# BE-U1000 register map
Vendor: BAIKAL ELECTRONICS, JSC; File version: 1.0
CPU: RISC-V r0p0, little endian, no MPU, no FPU, 3 interrupt priority bits
Registers are 32-bit, read-write, reset 0x0 unless marked. A register's access mark holds for its fields unless they carry their own. Offsets are from the block's base; [hi:lo] are bit positions.

## I2C0 — Inter Integrated Circuit Interface
Base 0x11004000
Same registers: I2C1 0x11005000, I2C2 0x13004000, I2C3 0x13005000
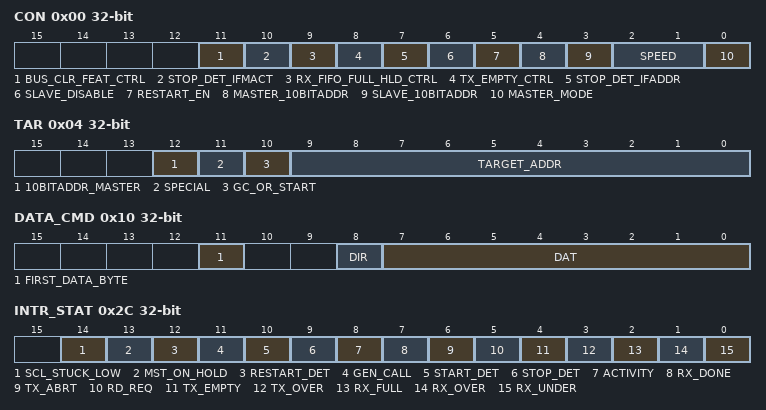
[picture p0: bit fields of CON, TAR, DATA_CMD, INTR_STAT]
0x00 CON — Control Register
  [11] BUS_CLR_FEAT_CTRL — Bus clear feature control
    0=DISABLE; 1=ENABLE
  [10] STOP_DET_IFMACT — STOP_DET interrupt mode if master active
    0=DISABLE; 1=ENABLE
  [9] RX_FIFO_FULL_HLD_CTRL — Hold bus when RX_FIFO is full
    0=DISABLE; 1=ENABLE
  [8] TX_EMPTY_CTRL — TX_EMPTY interrupt control
    0=DISABLE; 1=ENABLE
  [7] STOP_DET_IFADDR — STOP_DET interrupt mode if addressed
    0=DISABLE; 1=ENABLE
  [6] SLAVE_DISABLE — Slave mode disable
    0=DISABLE; 1=ENABLE
  [5] RESTART_EN — Master restart enable
    0=DISABLE; 1=ENABLE
  [4] MASTER_10BITADDR — Master addressing mode
    0=DISABLE; 1=ENABLE
  [3] SLAVE_10BITADDR — Slave addressing mode
    0=DISABLE; 1=ENABLE
  [2:1] SPEED — Bus speed
    1=STANDARD (Standard speed mode of operation); 2=FAST (Fast or Fast Plus speed mode of operation); 3=HIGH (High speed mode of operation)
  [0] MASTER_MODE — Master mode enable
    0=DISABLE; 1=ENABLE
0x04 TAR — Target Address Register
  [12] 10BITADDR_MASTER — Master addressing mode
    0=DISABLE; 1=ENABLE
  [11] SPECIAL — Select Device_ID or GC_OR_START to perform
    0=DISABLE; 1=ENABLE
  [10] GC_OR_START — Select GENERAL_CALL or START byte transmission
    0=DISABLE; 1=ENABLE
  [9:0] TARGET_ADDR — Target address
0x08 SAR — Slave Address Register
  [9:0] SLAVE_ADDR — Slave address
0x0C HS_MADDR — High Speed Master Mode Code Address Register
  [2:0] MASTER_CODE — HS mode master code
0x10 DATA_CMD — Rx/Tx Data Buffer and Command Register
  [11] FIRST_DATA_BYTE — Indicates the first data byte received after the address phase for receive transfer
    0=DISABLE; 1=ENABLE
  [8] DIR — Read or write select
    0=WRITE (Write command); 1=READ (Read command)
  [7:0] DAT — The data to be transmitted or received
0x14 SS_SCL_HCNT — Standard Speed SCL High Count Register
  [15:0] SS_SCL_HCNT — SCL clock high period count for standard speed
0x18 SS_SCL_LCNT — Standard Speed SCL Low Count Register
  [15:0] SS_SCL_LCNT — SCL clock low period count for standard speed
0x1C FS_SCL_HCNT — Fast Mode SCL High Count Register
  [15:0] FS_SCL_HCNT — SCL clock high period count for fast speed
0x20 FS_SCL_LCNT — Fast Mode SCL Low Count Register
  [15:0] FS_SCL_LCNT — SCL clock low period count for fast speed
0x24 HS_SCL_HCNT — High Speed SCL High Count Register
  [15:0] HS_SCL_HCNT — SCL clock high period count for high speed
0x28 HS_SCL_LCNT — High Speed SCL Low Count Register
  [15:0] HS_SCL_LCNT — SCL clock low period count for high speed
0x2C INTR_STAT — Interrupt Status Register
  [all] fields
    0=DISABLE; 1=ENABLE
  [14] SCL_STUCK_LOW — SCL_STUCK_AT_LOW interrupt status
  [13] MST_ON_HOLD — MASTER_ON_HOLD interrupt status
  [12] RESTART_DET — RESTART_DET interrupt status
  [11] GEN_CALL — GEN_CALL interrupt status
  [10] START_DET — START_DET interrupt status
  [9] STOP_DET — STOP_DET interrupt status
  [8] ACTIVITY — ACTIVITY interrupt status
  [7] RX_DONE — RX_DONE interrupt status
  [6] TX_ABRT — TX_ABRT interrupt status
  [5] RD_REQ — RD_REQ interrupt status
  [4] TX_EMPTY — TX_EMPTY interrupt status
  [3] TX_OVER — TX_OVER interrupt status
  [2] RX_FULL — RX_FULL interrupt status
  [1] RX_OVER — RX_OVER interrupt status
  [0] RX_UNDER — RX_UNDER interrupt status
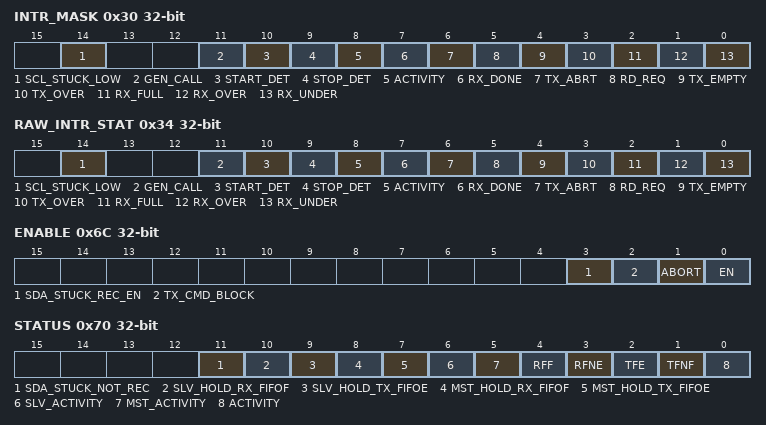
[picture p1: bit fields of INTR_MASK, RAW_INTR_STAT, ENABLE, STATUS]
0x30 INTR_MASK — Interrupt Mask Register
  [all] fields
    0=DISABLE; 1=ENABLE
  [14] SCL_STUCK_LOW — SCL_STUCK_AT_LOW interrupt mask
  [11] GEN_CALL — GEN_CALL interrupt mask
  [10] START_DET — START_DET interrupt mask
  [9] STOP_DET — STOP_DET interrupt mask
  [8] ACTIVITY — ACTIVITY interrupt mask
  [7] RX_DONE — RX_DONE interrupt mask
  [6] TX_ABRT — TX_ABRT interrupt mask
  [5] RD_REQ — RD_REQ interrupt mask
  [4] TX_EMPTY — TX_EMPTY interrupt mask
  [3] TX_OVER — TX_OVER interrupt mask
  [2] RX_FULL — RX_FULL interrupt mask
  [1] RX_OVER — RX_OVER interrupt mask
  [0] RX_UNDER — RX_UNDER interrupt mask
0x34 RAW_INTR_STAT — Raw Interrupt Status Register
  [all] fields
    0=DISABLE; 1=ENABLE
  [14] SCL_STUCK_LOW — SCL_STUCK_AT_LOW interrupt status
  [11] GEN_CALL — GEN_CALL interrupt status
  [10] START_DET — START_DET interrupt status
  [9] STOP_DET — STOP_DET interrupt status
  [8] ACTIVITY — ACTIVITY interrupt status
  [7] RX_DONE — RX_DONE interrupt status
  [6] TX_ABRT — TX_ABRT interrupt status
  [5] RD_REQ — RD_REQ interrupt status
  [4] TX_EMPTY — TX_EMPTY interrupt status
  [3] TX_OVER — TX_OVER interrupt status
  [2] RX_FULL — RX_FULL interrupt status
  [1] RX_OVER — RX_OVER interrupt status
  [0] RX_UNDER — RX_UNDER interrupt status
0x38 RX_TL — Rx FIFO Threshold Register
  [7:0] RX_TL — Rx FIFO threshold level
0x3C TX_TL — Tx FIFO Threshold Register
  [7:0] TX_TL — Tx FIFO threshold level
0x40 CLR_INTR — Clear Combined and Individual Interrupt Register
  [0] CLR_INTR — Clear the combined interrupt, all individual interrupts and TX_ABRT_SOURCE register
    0=DISABLE; 1=ENABLE
0x44 CLR_RX_UNDER — Clear RX_UNDER Interrupt Register
  [0] CLR_RX_UNDER — Clear RX_UNDER interrupt
    0=DISABLE; 1=ENABLE
0x48 CLR_RX_OVER — Clear RX_OVER Interrupt Register
  [0] CLR_RX_OVER — Clear RX_OVER interrupt
    0=DISABLE; 1=ENABLE
0x4C CLR_TX_OVER — Clear TX_OVER Interrupt Register
  [0] CLR_TX_OVER — Clear TX_OVER interrupt
    0=DISABLE; 1=ENABLE
0x50 CLR_RD_REQ — Clear RD_REQ Interrupt Register
  [0] CLR_RD_REQ — Clear RD_REQ interrupt
    0=DISABLE; 1=ENABLE
0x54 CLR_TX_ABRT — Clear TX_ABRT Interrupt Register
  [0] CLR_TX_ABRT — Clear TX_ABRT interrupt and TX_ABRT_SOURCE register
    0=DISABLE; 1=ENABLE
0x58 CLR_RX_DONE — Clear RX_DONE Interrupt Register
  [0] CLR_RX_DONE — Clear RX_DONE interrupt
    0=DISABLE; 1=ENABLE
0x5C CLR_ACTIVITY — Clear ACTIVITY Interrupt Register
  [0] CLR_ACTIVITY — Clear ACTIVITY interrupt
    0=DISABLE; 1=ENABLE
0x60 CLR_STOP_DET — Clear STOP_DET Interrupt Register
  [0] CLR_STOP_DET — Clear STOP_DET interrupt
    0=DISABLE; 1=ENABLE
0x64 CLR_START_DET — Clear START_DET Interrupt Register
  [0] CLR_START_DET — Clear START_DET interrupt
    0=DISABLE; 1=ENABLE
0x68 CLR_GEN_CALL — Clear GEN_CALL Interrupt Register
  [0] CLR_GEN_CALL — Clear GEN_CALL interrupt
    0=DISABLE; 1=ENABLE
0x6C ENABLE
  [all] fields
    0=DISABLE; 1=ENABLE
  [3] SDA_STUCK_REC_EN — Initiate SDA recovery mechanism
  [2] TX_CMD_BLOCK — Block the transmission of data
  [1] ABORT — Initiate the transfer abort
  [0] EN — Enable I2C
0x70 STATUS
  [all] fields
    0=DISABLE; 1=ENABLE
  [11] SDA_STUCK_NOT_REC — SDA stuck at low is not recovered after the recovery mechanism
  [10] SLV_HOLD_RX_FIFOF — BUS Hold due to Rx FIFO is full and an additional byte received
  [9] SLV_HOLD_TX_FIFOE — BUS Hold for the read request when Tx FIFO is empty
  [8] MST_HOLD_RX_FIFOF — BUS Hold due to Rx FIFO is full and an additional byte received
  [7] MST_HOLD_TX_FIFOE — Stall the write transfer when Tx FIFO is empty, no stop bit after the last byte
  [6] SLV_ACTIVITY — Slave FSM activity status
  [5] MST_ACTIVITY — Master FSM activity status
  [4] RFF — Rx FIFO completely full
  [3] RFNE — Rx FIFO not empty
  [2] TFE — Tx FIFO completely empty
  [1] TFNF — Tx FIFO not full
  [0] ACTIVITY — I2C activity status
0x74 TXFLR — Tx FIFO Level Register
  [3:0] TXFLR — Tx FIFO level
0x78 RXFLR — Rx FIFO Level Register
  [3:0] RXFLR — Rx FIFO level
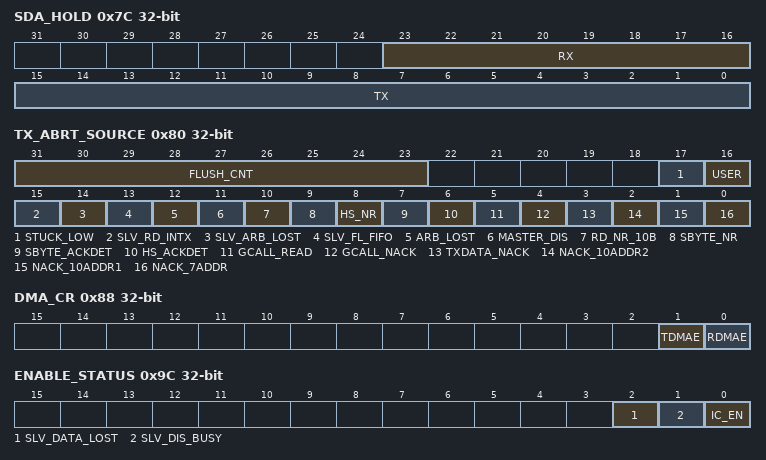
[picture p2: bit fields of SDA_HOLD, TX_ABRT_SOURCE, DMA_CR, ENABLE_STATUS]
0x7C SDA_HOLD — SDA Hold Time Length Register
  [23:16] RX — SDA hold time when receive
  [15:0] TX — SDA hold time when transmit
0x80 TX_ABRT_SOURCE — Tx Abort Source Register
  [31:23] FLUSH_CNT — The number of Tx FIFO data commands flushed due to TX_ABRT interrupt
  [17] STUCK_LOW — SDA stuck at low
    0=DISABLE; 1=ENABLE
  [16] USER — Master has detected the transfer abort
    0=DISABLE; 1=ENABLE
  [15] SLV_RD_INTX — Slave trying to transmit in read mode
    0=DISABLE; 1=ENABLE
  [14] SLV_ARB_LOST — Slave lost arbitration
    0=DISABLE; 1=ENABLE
  [13] SLV_FL_FIFO — Slave flushes existing data in Tx FIFO upon getting read
    0=DISABLE; 1=ENABLE
  [12] ARB_LOST — Master or slave transmitter lost arbitration
    0=DISABLE; 1=ENABLE
  [11] MASTER_DIS — Initiating master operation when master mode disabled
    0=DISABLE; 1=ENABLE
  [10] RD_NR_10B — Trying to read in 10-bit addressing mode when RESTART disabled
    0=DISABLE; 1=ENABLE
  [9] SBYTE_NR — Trying to send START when RESTART disabled
    0=DISABLE; 1=ENABLE
  [8] HS_NR — Trying to switch master to HS mode when RESTART disabled
    0=DISABLE; 1=ENABLE
  [7] SBYTE_ACKDET — START byte was acknowledged
    0=DISABLE; 1=ENABLE
  [6] HS_ACKDET — High speed master code was acknowledged
    0=DISABLE; 1=ENABLE
  [5] GCALL_READ — General Call is followed by the read from the bus
    0=DISABLE; 1=ENABLE
  [4] GCALL_NACK — No slave acknowledged the General Call
    0=DISABLE; 1=ENABLE
  [3] TXDATA_NACK — No acknowledgement of the data following the address
    0=DISABLE; 1=ENABLE
  [2] NACK_10ADDR2 — The second address byte was not acknowledged in 10-bit addressing mode
    0=DISABLE; 1=ENABLE
  [1] NACK_10ADDR1 — The first address byte was not acknowledged in 10-bit addressing mode
    0=DISABLE; 1=ENABLE
  [0] NACK_7ADDR — The address sent was not acknowledged in 7-bit addressing mode
    0=DISABLE; 1=ENABLE
0x88 DMA_CR — DMA Control Register
  [1] TDMAE — Transmit DMA enable
    0=DISABLE; 1=ENABLE
  [0] RDMAE — Receive DMA enable
    0=DISABLE; 1=ENABLE
0x8C DMA_TDLR — DMA Tx Data Level Register
  [2:0] DMA_TDLR — Transmit data level
0x90 DMA_RDLR — DMA Rx Data Level Register
  [2:0] DMA_RDLR — Receive data level
0x94 SDA_SETUP
  [7:0] SDA_SETUP — Time delay introduced in the rising edge of SCL
0x98 ACK_GENERAL_CALL
  [0] ACK_GENERAL_CALL — ACK for General Call
    0=DISABLE; 1=ENABLE
0x9C ENABLE_STATUS
  [all] fields
    0=DISABLE; 1=ENABLE
  [2] SLV_DATA_LOST — Slave received data lost
  [1] SLV_DIS_BUSY — Slave disabled while busy
  [0] IC_EN — IC enable status
0xA0 FS_SPKLEN — SS, FS, or FM Spike Suppression Limit Register
  [7:0] FS_SPKLEN — SS, FS or FM+ spike suppression limit
0xA4 HS_SPKLEN — HS Spike Suppression Limit Register
  [7:0] HS_SPKLEN — HS spike suppression limit
0xAC SCL_STUCK_AT_LOW_TIMEOUT — SLC Stuck at Low Timeout Register
0xB0 SDA_STUCK_AT_LOW_TIMEOUT
0xB4 CLR_SCL_STUCK_DET — Clear SCL Stuck at Low Detect Interrupt Register
  [0] CLR_SCL_STUCK_DET — Clear SCL_STUCK_AT_LOW interrupt
    0=DISABLE; 1=ENABLE
0xF0 REG_TIMEOUT_RST — Register Timeout Counter Reset Value
  [7:0] REG_TIMEOUT_RST — The reset value of REG_TIMEOUT counter register
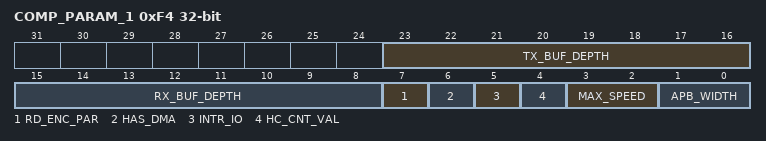
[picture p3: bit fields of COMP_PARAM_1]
0xF4 COMP_PARAM_1 — Component Parameter Register 1
  [23:16] TX_BUF_DEPTH — Depth of transmit buffer
  [15:8] RX_BUF_DEPTH — Depth of receive buffer
  [7] RD_ENC_PAR — Reading encoded parameters capability enable status
    0=DISABLE (Capability of reading encoded parameters is disabled); 1=ENABLE (Capability of reading encoded parameters is enabled)
  [6] HAS_DMA — DMA handshaking signals enable status
    0=DISABLE (DMA handshaking signals are disabled); 1=ENABLE (DMA handshaking signals are enabled)
  [5] INTR_IO — Interrupt outputs mode
    0=INDIVIDUAL (Individual interrupt outputs); 1=COMBINED (Combined interrupt outputs)
  [4] HC_CNT_VAL — Count values setting mode
    0=DISABLE (Programmable count values); 1=ENABLE (Hard code the count values)
  [3:2] MAX_SPEED — Max speed mode
    1=STD (Max speed is Standard mode); 2=FAST (Max speed is Fast mode); 3=HIGH (Max speed is High mode)
  [1:0] APB_WIDTH — APB data bus width
    0=8BITS (APB data bus width is 8 bits); 1=16BITS (APB data bus width is 16 bits); 2=32BITS (APB data bus width is 32 bits)
0xF8 COMP_VERSION — Component Version Register
  [31:0] COMP_VERSION — I2C component version
0xFC COMP_TYPE — Component Type Register
  [31:0] COMP_TYPE — I2C component type
